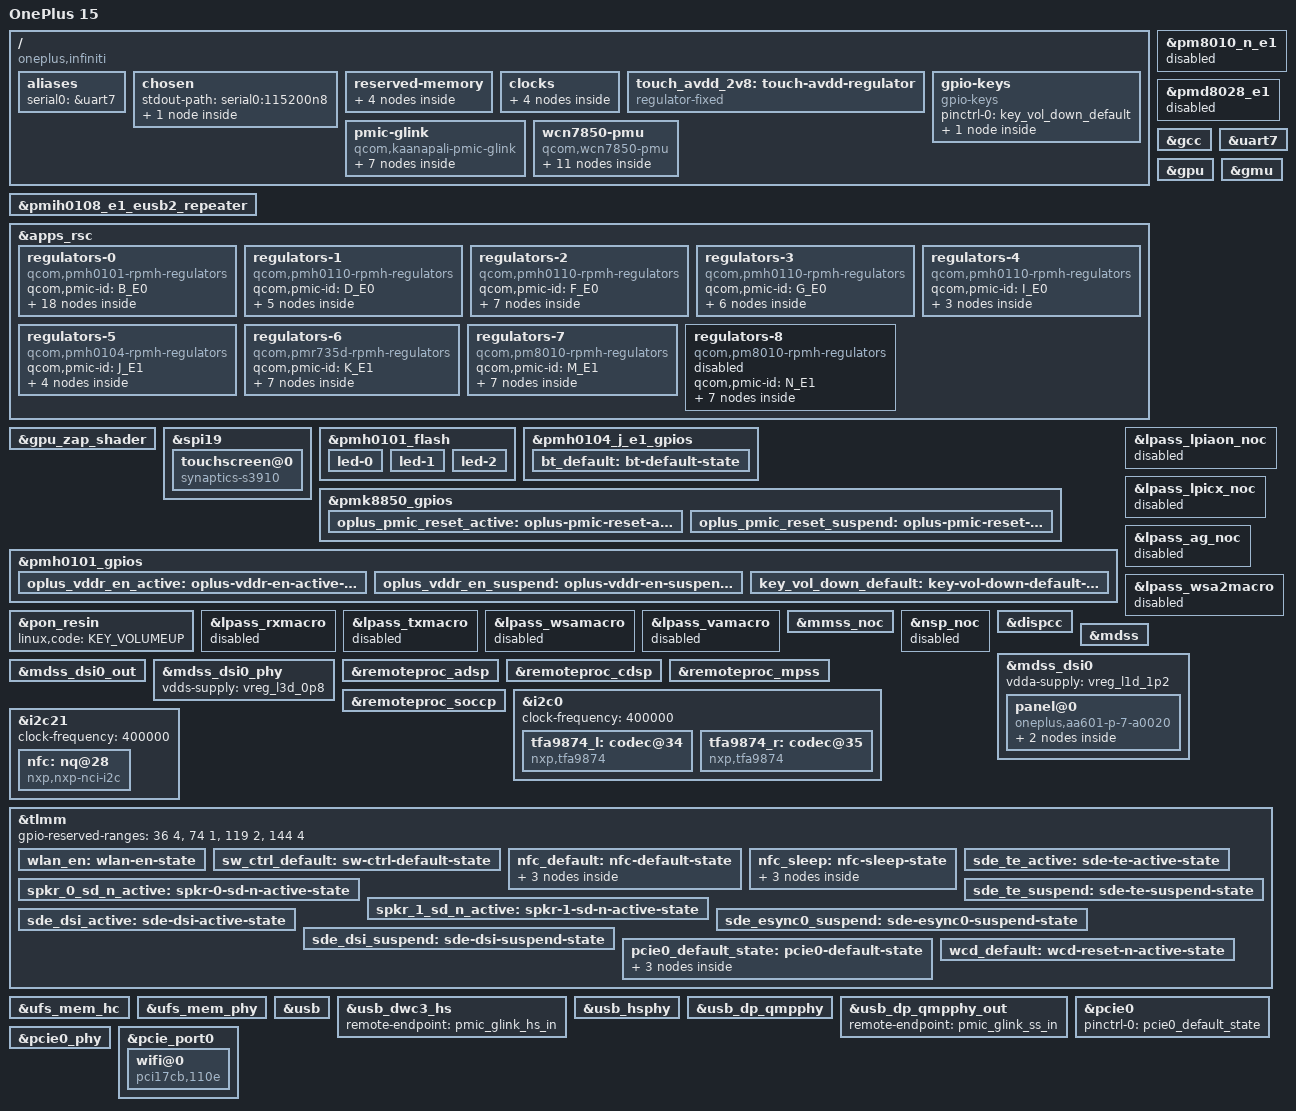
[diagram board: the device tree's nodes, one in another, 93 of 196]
// SPDX-License-Identifier: BSD-3-Clause
/dts-v1/;

#include <dt-bindings/arm/qcom,ids.h>
#include <dt-bindings/gpio/gpio.h>
#include <dt-bindings/input/linux-event-codes.h>
#include <dt-bindings/leds/common.h>
#include <dt-bindings/regulator/qcom,rpmh-regulator.h>
#include "kaanapali.dtsi"

#include "pm8010-kaanapali.dtsi"     /* SPMI1: SID-12/13   */
#include "pmd8028-kaanapali.dtsi"    /* SPMI1: SID-4       */
#include "pmh0101.dtsi"              /* SPMI0: SID-1       */
#include "pmh0104-kaanapali.dtsi"    /* SPMI1: SID-9       */
#include "pmh0110-kaanapali.dtsi"    /* SPMI0: SID-3/5/6/8 */
#include "pmih0108-kaanapali.dtsi"   /* SPMI1: SID-7       */
#include "pmk8850.dtsi"              /* SPMI0: SID-0       */
#include "pmr735d-kaanapali.dtsi"    /* SPMI1: SID-10      */

/delete-node/ &rmtfs_mem;

/ {
	model = "OnePlus 15";
	compatible = "oneplus,infiniti", "qcom,kaanapali";
	chassis-type = "handset";

	/* required for bootloader to select correct board */
	qcom,msm-id = <QCOM_ID_SM8850 0x20000>; /* SM8850 v2.0 */
	qcom,board-id = <0 0>;

	aliases {
		serial0 = &uart7;
	};

	chosen {
		#address-cells = <2>;
		#size-cells = <2>;
		ranges;

		stdout-path = "serial0:115200n8";

		framebuffer: framebuffer@b8000000 {
			compatible = "simple-framebuffer";
			reg = <0x0 0xfc800000 0x0 0x2b00000>;
			width = <1272>;
			height = <2772>;
			stride = <(1272 * 4)>;
			format = "a8r8g8b8";
		};
	};

	reserved-memory {

		bootloader_log_mem: botloader_mem@81ce4000 {
			reg = <0 0x81ce4000 0 0x10000>;
		};

		dump_device_info_mem: device_info_mem@a7f00000 {
			reg = <0 0xa7f00000 0 0x8000>;
			no-map;
		};

		/*
		 * The bootloader will only keep display hardware enabled
		 * if this memory region is named exactly 'splash_region'
		 */

		splash_memory: splash_region@fc800000 {
			reg = <0x0 0xfc800000 0x0 0x2b00000>;
			no-map;
		};

		/*
		 * The rmtfs memory region in downstream is 'dynamically allocated'
		 * but given the same address every time. Hard code it as this address is
		 * where the modem firmware expects it to be.
		 */
		rmtfs_mem: memory@d0d00000 {
			compatible = "qcom,rmtfs-mem";
			reg = <0x0 0xd0d00000 0x0 0x400000>;
			no-map;

			qcom,client-id = <1>;
			qcom,vmid = <QCOM_SCM_VMID_MSS_MSA>;
		};

	};

	/*
	 * Display bring-up: COLD-PROBE (mirrors the working Nubia Z80 Ultra kaanapali
	 * reference, same SoC). NO simple-framebuffer node and NO
	 * qcom,skip-mdss-reset: the UEFI continuous-splash handoff was the cause of
	 * the rainbow-bands / green-line freeze (simplefb clk_prepare_enable, or
	 * msm_mdss_enable() on the live UEFI-scanout MDP -> AXI/NoC stall). Cold-
	 * probe: msm_mdss_reset() idles the MDP first, the panel driver brings the
	 * display up later at the DRM modeset. Console is on serial0 (UART), not the
	 * framebuffer. The MDSS/dispcc/dsi0/dsi0_phy/mmss_noc nodes are enabled
	 * below; GPU/GMU/zap enabled for Adreno bring-up (stock PAS; SEA fixed
	 * in Mu-Silicium EFI memory map Reserv carveouts, not kernel tzmem).
	 */

	clocks {
		xo_board: xo-board {
			compatible = "fixed-clock";
			clock-frequency = <76800000>;
			#clock-cells = <0>;
		};

		sleep_clk: sleep-clk {
			compatible = "fixed-clock";
			clock-frequency = <32000>;
			#clock-cells = <0>;
		};

		bi_tcxo_div2: bi-tcxo-div2-clk {
			compatible = "fixed-factor-clock";
			#clock-cells = <0>;

			clocks = <&rpmhcc RPMH_CXO_CLK>;
			clock-mult = <1>;
			clock-div = <2>;
		};

		bi_tcxo_ao_div2: bi-tcxo-ao-div2-clk {
			compatible = "fixed-factor-clock";
			#clock-cells = <0>;

			clocks = <&rpmhcc RPMH_CXO_CLK_A>;
			clock-mult = <1>;
			clock-div = <2>;
		};
	};

	/*
	 * Touch AVDD is GPIO-switched on PMH0110_D GPIO9 (not L14B).
	 * Model as regulator-fixed for mainline avdd-supply consumers.
	 */
	touch_avdd_2v8: touch-avdd-regulator {
		compatible = "regulator-fixed";
		regulator-name = "touch_avdd_2v8";
		regulator-min-microvolt = <2800000>;
		regulator-max-microvolt = <2800000>;
		gpio = <&pmh0110_d_e0_gpios 9 GPIO_ACTIVE_HIGH>;
		enable-active-high;
	};

	gpio-keys {
		compatible = "gpio-keys";

		/*
		 * Infiniti (canoe-mtp / 24831): volume-down is wired to
		 * PMH0101 GPIO 6, not TLMM 101 (that is kaanapali-mtp/QRD).
		 * Volume-up stays on pmk8850 pon_resin.
		 */
		pinctrl-0 = <&key_vol_down_default>;
		pinctrl-names = "default";

		key-volume-down {
			label = "Volume Down";
			linux,code = <KEY_VOLUMEDOWN>;
			gpios = <&pmh0101_gpios 6 GPIO_ACTIVE_LOW>;
			debounce-interval = <32>;
			linux,can-disable;
			wakeup-source;
		};
	};

	pmic-glink {
		compatible = "qcom,kaanapali-pmic-glink";
		#address-cells = <1>;
		#size-cells = <0>;

		connector@0 {
			compatible = "usb-c-connector";
			reg = <0>;
			power-role = "dual";
			data-role = "dual";

			ports {
				#address-cells = <1>;
				#size-cells = <0>;

				port@0 {
					reg = <0>;

					pmic_glink_hs_in: endpoint {
						remote-endpoint = <&usb_dwc3_hs>;
					};
				};

				port@1 {
					reg = <1>;

					pmic_glink_ss_in: endpoint {
						remote-endpoint = <&usb_dp_qmpphy_out>;
					};
				};

				port@2 {
					reg = <2>;

					// pmic_glink_sbu: endpoint {
					// 	remote-endpoint = <&fsa4480_sbu_mux>;
					// };
				};

			};
		};
	};

};

&pmih0108_e1_eusb2_repeater {
	qcom,tune-usb2-preem = /bits/ 8 <0x4>;
	qcom,tune-usb2-slew = /bits/ 8 <0x2>;
	qcom,tune-usb2-disc-thres = /bits/ 8 <0x7>;
	qcom,tune-usb2-amplitude = /bits/ 8 <0xe>;
	qcom,squelch-detector-bp = <(-2000)>;
	vdd18-supply = <&vreg_l15b_1p8>;
	vdd3-supply = <&vreg_l5b_3p1>;

	status = "okay";
};

/*
 * SPMI1 PMICs not present on the Infiniti variant. The downstream canoe DT
 * (a multi-SKU superset) declares pmd8028 @ SID 0x4 and pm8010_n @ SID 0xd, but
 * on this device the SPMI arbiter NACKs both USIDs (status 0x3) and the RPMh
 * Command DB has no L*N_E1 entries, i.e. the silicon is absent. Disable the
 * nodes so the generic pmic-spmi driver does not try to probe them (avoids the
 * "transaction failed" WARN + -EIO probe failures). pm8010_m @ SID 0xc IS
 * present and stays enabled.
 */
&pm8010_n_e1 {
	status = "disabled";
};

&pmd8028_e1 {
	status = "disabled";
};

&apps_rsc {
	regulators-0 {
		compatible = "qcom,pmh0101-rpmh-regulators";
		qcom,pmic-id = "B_E0";

		vreg_bob1: bob1 {
			regulator-name = "vreg_bob1";
			regulator-min-microvolt = <3008000>;
			regulator-max-microvolt = <4000000>;
			regulator-initial-mode = <RPMH_REGULATOR_MODE_HPM>;
		};

		vreg_bob2: bob2 {
			regulator-name = "vreg_bob2";
			regulator-min-microvolt = <2704000>;
			regulator-max-microvolt = <3552000>;
			regulator-initial-mode = <RPMH_REGULATOR_MODE_HPM>;
		};

		vreg_l1b_1p8: ldo1 {
			regulator-name = "vreg_l1b_1p8";
			regulator-min-microvolt = <1800000>;
			regulator-max-microvolt = <1800000>;
			regulator-initial-mode = <RPMH_REGULATOR_MODE_AUTO>;
			regulator-allow-set-load;
			regulator-allowed-modes = <RPMH_REGULATOR_MODE_LPM
						   RPMH_REGULATOR_MODE_AUTO>;
		};

		vreg_l2b_3p0: ldo2 {
			regulator-name = "vreg_l2b_3p0";
			regulator-min-microvolt = <3008000>;
			regulator-max-microvolt = <3048000>;
			regulator-initial-mode = <RPMH_REGULATOR_MODE_AUTO>;
			regulator-allow-set-load;
			regulator-allowed-modes = <RPMH_REGULATOR_MODE_LPM
						   RPMH_REGULATOR_MODE_AUTO>;
		};

		vreg_l4b_1p8: ldo4 {
			regulator-name = "vreg_l4b_1p8";
			regulator-min-microvolt = <1800000>;
			regulator-max-microvolt = <1800000>;
			regulator-initial-mode = <RPMH_REGULATOR_MODE_AUTO>;
			regulator-allow-set-load;
			regulator-allowed-modes = <RPMH_REGULATOR_MODE_LPM
						   RPMH_REGULATOR_MODE_AUTO>;
		};

		vreg_l5b_3p1: ldo5 {
			regulator-name = "vreg_l5b_3p1";
			regulator-min-microvolt = <3100000>;
			regulator-max-microvolt = <3148000>;
			regulator-initial-mode = <RPMH_REGULATOR_MODE_AUTO>;
			regulator-allow-set-load;
			regulator-allowed-modes = <RPMH_REGULATOR_MODE_LPM
						   RPMH_REGULATOR_MODE_AUTO>;
		};

		vreg_l6b_1p8: ldo6 {
			regulator-name = "vreg_l6b_1p8";
			regulator-min-microvolt = <1800000>;
			regulator-max-microvolt = <3008000>;
			regulator-initial-mode = <RPMH_REGULATOR_MODE_AUTO>;
			regulator-allow-set-load;
			regulator-allowed-modes = <RPMH_REGULATOR_MODE_LPM
						   RPMH_REGULATOR_MODE_AUTO>;
		};

		vreg_l7b_1p8: ldo7 {
			regulator-name = "vreg_l7b_1p8";
			regulator-min-microvolt = <1800000>;
			regulator-max-microvolt = <3008000>;
			regulator-initial-mode = <RPMH_REGULATOR_MODE_AUTO>;
			regulator-allow-set-load;
			regulator-allowed-modes = <RPMH_REGULATOR_MODE_LPM
						   RPMH_REGULATOR_MODE_AUTO>;
		};

		vreg_l8b_1p8: ldo8 {
			regulator-name = "vreg_l8b_1p8";
			regulator-min-microvolt = <1800000>;
			regulator-max-microvolt = <3008000>;
			regulator-initial-mode = <RPMH_REGULATOR_MODE_AUTO>;
			regulator-allow-set-load;
			regulator-allowed-modes = <RPMH_REGULATOR_MODE_LPM
						   RPMH_REGULATOR_MODE_AUTO>;
		};

		vreg_l9b_2p9: ldo9 {
			regulator-name = "vreg_l9b_2p9";
			regulator-min-microvolt = <2960000>;
			regulator-max-microvolt = <3008000>;
			regulator-initial-mode = <RPMH_REGULATOR_MODE_HPM>;
			regulator-allow-set-load;
			regulator-allowed-modes = <RPMH_REGULATOR_MODE_LPM
						   RPMH_REGULATOR_MODE_HPM>;
		};

		vreg_l10b_1p8: ldo10 {
			regulator-name = "vreg_l10b_1p8";
			regulator-min-microvolt = <1800000>;
			regulator-max-microvolt = <1800000>;
			regulator-initial-mode = <RPMH_REGULATOR_MODE_AUTO>;
			regulator-allow-set-load;
			regulator-allowed-modes = <RPMH_REGULATOR_MODE_LPM
						   RPMH_REGULATOR_MODE_AUTO>;
		};

		pmh0101_l11: vreg_l11b_1p0: ldo11 {
			regulator-name = "vreg_l11b_1p0";
			regulator-min-microvolt = <1200000>;
			regulator-max-microvolt = <1200000>;
			regulator-initial-mode = <RPMH_REGULATOR_MODE_AUTO>;
			regulator-allow-set-load;
			regulator-allowed-modes = <RPMH_REGULATOR_MODE_LPM
						   RPMH_REGULATOR_MODE_AUTO>;
		};

		pmh0101_l12: vreg_l12b_1p8: ldo12 {
			regulator-name = "vreg_l12b_1p8";
			regulator-min-microvolt = <1800000>;
			regulator-max-microvolt = <1800000>;
			regulator-initial-mode = <RPMH_REGULATOR_MODE_AUTO>;
			regulator-allow-set-load;
			regulator-allowed-modes = <RPMH_REGULATOR_MODE_LPM
						   RPMH_REGULATOR_MODE_AUTO>;
		};

		pmh0101_l13: vreg_l13b_3p0: ldo13 {
			regulator-name = "vreg_l13b_3p0";
			regulator-min-microvolt = <3000000>;
			regulator-max-microvolt = <3000000>;
			regulator-initial-mode = <RPMH_REGULATOR_MODE_AUTO>;
			regulator-allow-set-load;
			regulator-allowed-modes = <RPMH_REGULATOR_MODE_LPM
						   RPMH_REGULATOR_MODE_AUTO>;
		};

		vreg_l14b_3p2: ldo14 {
			regulator-name = "vreg_l14b_3p2";
			regulator-min-microvolt = <3200000>;
			regulator-max-microvolt = <3200000>;
			regulator-initial-mode = <RPMH_REGULATOR_MODE_AUTO>;
			regulator-allow-set-load;
			regulator-allowed-modes = <RPMH_REGULATOR_MODE_LPM
						   RPMH_REGULATOR_MODE_AUTO>;
		};

		vreg_l15b_1p8: ldo15 {
			regulator-name = "vreg_l15b_1p8";
			regulator-min-microvolt = <1800000>;
			regulator-max-microvolt = <1800000>;
			regulator-initial-mode = <RPMH_REGULATOR_MODE_AUTO>;
			regulator-allow-set-load;
			regulator-allowed-modes = <RPMH_REGULATOR_MODE_LPM
						   RPMH_REGULATOR_MODE_AUTO>;
		};

		vreg_l17b_2p5: ldo17 {
			regulator-name = "vreg_l17b_2p5";
			regulator-min-microvolt = <2504000>;
			regulator-max-microvolt = <2504000>;
			regulator-initial-mode = <RPMH_REGULATOR_MODE_HPM>;
			regulator-allow-set-load;
			regulator-allowed-modes = <RPMH_REGULATOR_MODE_LPM
						   RPMH_REGULATOR_MODE_HPM>;
		};

		vreg_l18b_1p2: ldo18 {
			regulator-name = "vreg_l18b_1p2";
			regulator-min-microvolt = <1200000>;
			regulator-max-microvolt = <1200000>;
			regulator-initial-mode = <RPMH_REGULATOR_MODE_AUTO>;
			regulator-allow-set-load;
			regulator-allowed-modes = <RPMH_REGULATOR_MODE_LPM
						   RPMH_REGULATOR_MODE_AUTO>;
		};
	};

	regulators-1 {
		compatible = "qcom,pmh0110-rpmh-regulators";
		qcom,pmic-id = "D_E0";

		vreg_s10d_1p0: smps10 {
			regulator-name = "vreg_s10d_1p0";
			regulator-min-microvolt = <1000000>;
			regulator-max-microvolt = <1100000>;
			regulator-initial-mode = <RPMH_REGULATOR_MODE_HPM>;
		};

		vreg_l1d_1p2: ldo1 {
			regulator-name = "vreg_l1d_1p2";
			regulator-min-microvolt = <1200000>;
			regulator-max-microvolt = <1256000>;
			regulator-initial-mode = <RPMH_REGULATOR_MODE_AUTO>;
			regulator-allow-set-load;
			regulator-allowed-modes = <RPMH_REGULATOR_MODE_LPM
						   RPMH_REGULATOR_MODE_AUTO>;
		};

		vreg_l2d_0p9: ldo2 {
			regulator-name = "vreg_l2d_0p9";
			regulator-min-microvolt = <912000>;
			regulator-max-microvolt = <958000>;
			regulator-initial-mode = <RPMH_REGULATOR_MODE_AUTO>;
			regulator-allow-set-load;
			regulator-allowed-modes = <RPMH_REGULATOR_MODE_LPM
						   RPMH_REGULATOR_MODE_AUTO>;
		};

		pmh0110_d_l3: vreg_l3d_0p8: ldo3 {
			regulator-name = "vreg_l3d_0p8";
			regulator-min-microvolt = <880000>;
			regulator-max-microvolt = <880000>;
			regulator-initial-mode = <RPMH_REGULATOR_MODE_AUTO>;
			regulator-allow-set-load;
			regulator-allowed-modes = <RPMH_REGULATOR_MODE_LPM
						   RPMH_REGULATOR_MODE_AUTO>;
		};

		vreg_l4d_1p2: ldo4 {
			regulator-name = "vreg_l4d_1p2";
			regulator-min-microvolt = <1200000>;
			regulator-max-microvolt = <1200000>;
			regulator-initial-mode = <RPMH_REGULATOR_MODE_AUTO>;
			regulator-allow-set-load;
			regulator-allowed-modes = <RPMH_REGULATOR_MODE_LPM
						   RPMH_REGULATOR_MODE_AUTO>;
		};
	};

	regulators-2 {
		compatible = "qcom,pmh0110-rpmh-regulators";
		qcom,pmic-id = "F_E0";

		vreg_s6f_0p5: smps6 {
			regulator-name = "vreg_s6f_0p5";
			regulator-min-microvolt = <300000>;
			regulator-max-microvolt = <570000>;
			regulator-initial-mode = <RPMH_REGULATOR_MODE_HPM>;
		};

		vreg_s7f_1p2: smps7 {
			regulator-name = "vreg_s7f_1p2";
			regulator-min-microvolt = <1224000>;
			regulator-max-microvolt = <1372000>;
			regulator-initial-mode = <RPMH_REGULATOR_MODE_HPM>;
		};

		vreg_s8f_1p8: smps8 {
			regulator-name = "vreg_s8f_1p8";
			regulator-min-microvolt = <1800000>;
			regulator-max-microvolt = <2000000>;
			regulator-initial-mode = <RPMH_REGULATOR_MODE_HPM>;
		};

		vreg_l1f_1p2: ldo1 {
			regulator-name = "vreg_l1f_1p2";
			regulator-min-microvolt = <1200000>;
			regulator-max-microvolt = <1200000>;
			regulator-initial-mode = <RPMH_REGULATOR_MODE_AUTO>;
			regulator-allow-set-load;
			regulator-allowed-modes = <RPMH_REGULATOR_MODE_LPM
						   RPMH_REGULATOR_MODE_AUTO>;
		};

		vreg_l2f_1p2: ldo2 {
			regulator-name = "vreg_l2f_1p2";
			regulator-min-microvolt = <1200000>;
			regulator-max-microvolt = <1200000>;
			regulator-initial-mode = <RPMH_REGULATOR_MODE_AUTO>;
			regulator-allow-set-load;
			regulator-allowed-modes = <RPMH_REGULATOR_MODE_LPM
						   RPMH_REGULATOR_MODE_AUTO>;
		};

		vreg_l3f_0p8: ldo3 {
			regulator-name = "vreg_l3f_0p8";
			regulator-min-microvolt = <880000>;
			regulator-max-microvolt = <936000>;
			regulator-initial-mode = <RPMH_REGULATOR_MODE_AUTO>;
			regulator-allow-set-load;
			regulator-allowed-modes = <RPMH_REGULATOR_MODE_LPM
						   RPMH_REGULATOR_MODE_AUTO>;
		};

		vreg_l4f_0p8: ldo4 {
			regulator-name = "vreg_l4f_0p8";
			regulator-min-microvolt = <880000>;
			regulator-max-microvolt = <912000>;
			regulator-initial-mode = <RPMH_REGULATOR_MODE_AUTO>;
			regulator-allow-set-load;
			regulator-allowed-modes = <RPMH_REGULATOR_MODE_LPM
						   RPMH_REGULATOR_MODE_AUTO>;
		};
	};

	regulators-3 {
		compatible = "qcom,pmh0110-rpmh-regulators";
		qcom,pmic-id = "G_E0";

		vreg_s7g_0p9: smps7 {
			regulator-name = "vreg_s7g_0p9";
			regulator-min-microvolt = <880000>;
			regulator-max-microvolt = <1100000>;
			regulator-initial-mode = <RPMH_REGULATOR_MODE_HPM>;
		};

		vreg_s9g_1p0: smps9 {
			regulator-name = "vreg_s9g_1p0";
			regulator-min-microvolt = <1000000>;
			regulator-max-microvolt = <1100000>;
			regulator-initial-mode = <RPMH_REGULATOR_MODE_HPM>;
		};

		vreg_l1g_1p2: ldo1 {
			regulator-name = "vreg_l1g_1p2";
			regulator-min-microvolt = <1200000>;
			regulator-max-microvolt = <1200000>;
			regulator-initial-mode = <RPMH_REGULATOR_MODE_AUTO>;
			regulator-allow-set-load;
			regulator-allowed-modes = <RPMH_REGULATOR_MODE_LPM
						   RPMH_REGULATOR_MODE_AUTO>;
		};

		vreg_l2g_1p8: ldo2 {
			regulator-name = "vreg_l2g_1p8";
			regulator-min-microvolt = <1800000>;
			regulator-max-microvolt = <1800000>;
			regulator-initial-mode = <RPMH_REGULATOR_MODE_AUTO>;
			regulator-allow-set-load;
			regulator-allowed-modes = <RPMH_REGULATOR_MODE_LPM
						   RPMH_REGULATOR_MODE_AUTO>;
		};

		vreg_l3g_1p2: ldo3 {
			regulator-name = "vreg_l3g_1p2";
			regulator-min-microvolt = <1200000>;
			regulator-max-microvolt = <1200000>;
			regulator-initial-mode = <RPMH_REGULATOR_MODE_AUTO>;
			regulator-allow-set-load;
			regulator-allowed-modes = <RPMH_REGULATOR_MODE_LPM
						   RPMH_REGULATOR_MODE_AUTO>;
		};

		vreg_l4g_0p9: ldo4 {
			regulator-name = "vreg_l4g_0p9";
			regulator-min-microvolt = <912000>;
			regulator-max-microvolt = <912000>;
			regulator-initial-mode = <RPMH_REGULATOR_MODE_AUTO>;
			regulator-allow-set-load;
			regulator-allowed-modes = <RPMH_REGULATOR_MODE_LPM
						   RPMH_REGULATOR_MODE_AUTO>;
		};
	};

	regulators-4 {
		compatible = "qcom,pmh0110-rpmh-regulators";
		qcom,pmic-id = "I_E0";

		vreg_s7i_0p9: smps7 {
			regulator-name = "vreg_s7i_0p9";
			regulator-min-microvolt = <900000>;
			regulator-max-microvolt = <972000>;
			regulator-initial-mode = <RPMH_REGULATOR_MODE_HPM>;
		};

		vreg_l2i_1p2: ldo2 {
			regulator-name = "vreg_l2i_1p2";
			regulator-min-microvolt = <1200000>;
			regulator-max-microvolt = <1200000>;
			regulator-initial-mode = <RPMH_REGULATOR_MODE_AUTO>;
			regulator-allow-set-load;
			regulator-allowed-modes = <RPMH_REGULATOR_MODE_LPM
						   RPMH_REGULATOR_MODE_AUTO>;
		};

		vreg_l3i_0p8: ldo3 {
			regulator-name = "vreg_l3i_0p8";
			regulator-min-microvolt = <880000>;
			regulator-max-microvolt = <920000>;
			regulator-initial-mode = <RPMH_REGULATOR_MODE_AUTO>;
			regulator-allow-set-load;
			regulator-allowed-modes = <RPMH_REGULATOR_MODE_LPM
						   RPMH_REGULATOR_MODE_AUTO>;
		};
	};

	regulators-5 {
		compatible = "qcom,pmh0104-rpmh-regulators";
		qcom,pmic-id = "J_E1";

		vreg_s1j_0p8: smps1 {
			regulator-name = "vreg_s1j_0p8";
			regulator-min-microvolt = <400000>;
			regulator-max-microvolt = <1000000>;
			regulator-initial-mode = <RPMH_REGULATOR_MODE_HPM>;
		};

		vreg_s2j_0p8: smps2 {
			regulator-name = "vreg_s2j_0p8";
			regulator-min-microvolt = <500000>;
			regulator-max-microvolt = <1100000>;
			regulator-initial-mode = <RPMH_REGULATOR_MODE_HPM>;
		};

		vreg_s3j_1p2: smps3 {
			regulator-name = "vreg_s3j_1p2";
			regulator-min-microvolt = <1200000>;
			regulator-max-microvolt = <1300000>;
			regulator-initial-mode = <RPMH_REGULATOR_MODE_HPM>;
		};

		vreg_s4j_0p7: smps4 {
			regulator-name = "vreg_s4j_0p7";
			regulator-min-microvolt = <300000>;
			regulator-max-microvolt = <1000000>;
			regulator-initial-mode = <RPMH_REGULATOR_MODE_HPM>;
		};
	};

	regulators-6 {
		compatible = "qcom,pmr735d-rpmh-regulators";
		qcom,pmic-id = "K_E1";

		vreg_l1k_0p8: ldo1 {
			regulator-name = "vreg_l1k_0p8";
			regulator-min-microvolt = <300000>;
			regulator-max-microvolt = <1100000>;
			regulator-initial-mode = <RPMH_REGULATOR_MODE_HPM>;
			regulator-allow-set-load;
			regulator-allowed-modes = <RPMH_REGULATOR_MODE_LPM
						   RPMH_REGULATOR_MODE_HPM>;
		};

		vreg_l2k_0p7: ldo2 {
			regulator-name = "vreg_l2k_0p7";
			regulator-min-microvolt = <700000>;
			regulator-max-microvolt = <1000000>;
			regulator-initial-mode = <RPMH_REGULATOR_MODE_HPM>;
			regulator-allow-set-load;
			regulator-allowed-modes = <RPMH_REGULATOR_MODE_LPM
						   RPMH_REGULATOR_MODE_HPM>;
		};

		vreg_l3k_1p2: ldo3 {
			regulator-name = "vreg_l3k_1p2";
			regulator-min-microvolt = <1200000>;
			regulator-max-microvolt = <1200000>;
			regulator-initial-mode = <RPMH_REGULATOR_MODE_HPM>;
			regulator-allow-set-load;
			regulator-allowed-modes = <RPMH_REGULATOR_MODE_LPM
						   RPMH_REGULATOR_MODE_HPM>;
		};

		vreg_l4k_1p0: ldo4 {
			regulator-name = "vreg_l4k_1p0";
			regulator-min-microvolt = <1000000>;
			regulator-max-microvolt = <1200000>;
			regulator-initial-mode = <RPMH_REGULATOR_MODE_HPM>;
			regulator-allow-set-load;
			regulator-allowed-modes = <RPMH_REGULATOR_MODE_LPM
						   RPMH_REGULATOR_MODE_HPM>;
		};

		vreg_l5k_0p7: ldo5 {
			regulator-name = "vreg_l5k_0p7";
			regulator-min-microvolt = <700000>;
			regulator-max-microvolt = <1000000>;
			regulator-initial-mode = <RPMH_REGULATOR_MODE_HPM>;
			regulator-allow-set-load;
			regulator-allowed-modes = <RPMH_REGULATOR_MODE_LPM
						   RPMH_REGULATOR_MODE_HPM>;
		};

		vreg_l6k_1p7: ldo6 {
			regulator-name = "vreg_l6k_1p7";
			regulator-min-microvolt = <1700000>;
			regulator-max-microvolt = <2000000>;
			regulator-initial-mode = <RPMH_REGULATOR_MODE_HPM>;
			regulator-allow-set-load;
			regulator-allowed-modes = <RPMH_REGULATOR_MODE_LPM
						   RPMH_REGULATOR_MODE_HPM>;
		};

		vreg_l7k_0p7: ldo7 {
			regulator-name = "vreg_l7k_0p7";
			regulator-min-microvolt = <700000>;
			regulator-max-microvolt = <848000>;
			regulator-initial-mode = <RPMH_REGULATOR_MODE_HPM>;
			regulator-allow-set-load;
			regulator-allowed-modes = <RPMH_REGULATOR_MODE_LPM
						   RPMH_REGULATOR_MODE_HPM>;
		};
	};

	regulators-7 {
		compatible = "qcom,pm8010-rpmh-regulators";
		qcom,pmic-id = "M_E1";

		vreg_l1m_1p0: ldo1 {
			regulator-name = "vreg_l1m_1p0";
			regulator-min-microvolt = <1000000>;
			regulator-max-microvolt = <1200000>;
			regulator-initial-mode = <RPMH_REGULATOR_MODE_HPM>;
			regulator-allow-set-load;
			regulator-allowed-modes = <RPMH_REGULATOR_MODE_LPM
						   RPMH_REGULATOR_MODE_HPM>;
		};

		vreg_l2m_1p0: ldo2 {
			regulator-name = "vreg_l2m_1p0";
			regulator-min-microvolt = <1096000>;
			regulator-max-microvolt = <1104000>;
			regulator-initial-mode = <RPMH_REGULATOR_MODE_HPM>;
			regulator-allow-set-load;
			regulator-allowed-modes = <RPMH_REGULATOR_MODE_LPM
						   RPMH_REGULATOR_MODE_HPM>;
		};

		vreg_l3m_2p8: ldo3 {
			regulator-name = "vreg_l3m_2p8";
			regulator-min-microvolt = <2800000>;
			regulator-max-microvolt = <2900000>;
			regulator-initial-mode = <RPMH_REGULATOR_MODE_HPM>;
		};

		vreg_l4m_2p2: ldo4 {
			regulator-name = "vreg_l4m_2p2";
			regulator-min-microvolt = <2200000>;
			regulator-max-microvolt = <2800000>;
			regulator-initial-mode = <RPMH_REGULATOR_MODE_HPM>;
		};

		vreg_l5m_1p2: ldo5 {
			regulator-name = "vreg_l5m_1p2";
			regulator-min-microvolt = <1200000>;
			regulator-max-microvolt = <1800000>;
			regulator-initial-mode = <RPMH_REGULATOR_MODE_HPM>;
		};

		vreg_l6m_2p2: ldo6 {
			regulator-name = "vreg_l6m_2p2";
			regulator-min-microvolt = <2200000>;
			regulator-max-microvolt = <2200000>;
			regulator-initial-mode = <RPMH_REGULATOR_MODE_HPM>;
		};

		vreg_l7m_2p8: ldo7 {
			regulator-name = "vreg_l7m_2p8";
			regulator-min-microvolt = <2800000>;
			regulator-max-microvolt = <2800000>;
			regulator-initial-mode = <RPMH_REGULATOR_MODE_HPM>;
		};
	};

	regulators-8 {
		compatible = "qcom,pm8010-rpmh-regulators";
		qcom,pmic-id = "N_E1";

		/* pm8010_n (SID 0xd) absent on Infiniti: L*N_E1 not in the
		 * RPMh Command DB. Disable so qcom-rpmh-regulator does not look
		 * up L1N_E1 (and L2N..L7N) and fail with -ENODEV.
		 */
		status = "disabled";

		vreg_l1n_1p1: ldo1 {
			regulator-name = "vreg_l1n_1p1";
			regulator-min-microvolt = <1096000>;
			regulator-max-microvolt = <1200000>;
			regulator-initial-mode = <RPMH_REGULATOR_MODE_HPM>;
			regulator-allow-set-load;
			regulator-allowed-modes = <RPMH_REGULATOR_MODE_LPM
						   RPMH_REGULATOR_MODE_HPM>;
		};

		vreg_l2n_1p2: ldo2 {
			regulator-name = "vreg_l2n_1p2";
			regulator-min-microvolt = <1200000>;
			regulator-max-microvolt = <1200000>;
			regulator-initial-mode = <RPMH_REGULATOR_MODE_HPM>;
			regulator-allow-set-load;
			regulator-allowed-modes = <RPMH_REGULATOR_MODE_LPM
						   RPMH_REGULATOR_MODE_HPM>;
		};

		vreg_l3n_1p8: ldo3 {
			regulator-name = "vreg_l3n_1p8";
			regulator-min-microvolt = <1800000>;
			regulator-max-microvolt = <1800000>;
			regulator-initial-mode = <RPMH_REGULATOR_MODE_HPM>;
		};

		vreg_l4n_1p8: ldo4 {
			regulator-name = "vreg_l4n_1p8";
			regulator-min-microvolt = <1800000>;
			regulator-max-microvolt = <1800000>;
			regulator-initial-mode = <RPMH_REGULATOR_MODE_HPM>;
		};

		vreg_l5n_2p8: ldo5 {
			regulator-name = "vreg_l5n_2p8";
			regulator-min-microvolt = <2800000>;
			regulator-max-microvolt = <2800000>;
			regulator-initial-mode = <RPMH_REGULATOR_MODE_HPM>;
		};

		vreg_l6n_2p8: ldo6 {
			regulator-name = "vreg_l6n_2p8";
			regulator-min-microvolt = <2800000>;
			regulator-max-microvolt = <2800000>;
			regulator-initial-mode = <RPMH_REGULATOR_MODE_HPM>;
		};

		vreg_l7n_3p3: ldo7 {
			regulator-name = "vreg_l7n_3p3";
			regulator-min-microvolt = <3304000>;
			regulator-max-microvolt = <3304000>;
			regulator-initial-mode = <RPMH_REGULATOR_MODE_HPM>;
		};
	};
};

&gcc {
	status = "okay";
};

&uart7 {
	status = "okay";
};

&gpu {
	/* GPU + GMU; zap via &gpu_zap_shader (stock qcom_mdt_load PAS). */
	status = "okay";
};

&gmu {
	/* Required alongside &gpu for the a8xx bring-up path. */
	status = "okay";
};

&gpu_zap_shader {
	/*
	 * Enable zap PAS (stock qcom_mdt_load + pas_auth_and_reset). The SEA
	 * on dma_alloc_coherent(__scm->dev) was fixed by Mu-Silicium EFI
	 * memory-map Reserv carveouts (not by use_tzmem). SECVID_TRUST_CNTL=0
	 * alone is ignored by TZ → hangcheck 00880005 without zap.
	 * gpu_microcode_mem is 8 KiB (same as canoe.dtsi); LOAD segment of
	 * Infiniti zap is ~1 KiB — no enlarge needed.
	 * Blob: qcom/kaanapali/OnePlus/Infiniti/gen80200_zap.mbn
	 * sha256 fc6e4d0d0cd7269b7a03c44d07dde677621c0a8d566c6b94fc20860f2e714b0b
	 */
	status = "okay";
	firmware-name = "qcom/kaanapali/OnePlus/Infiniti/gen80200_zap.mbn";
};

&spi19 {
	status = "okay";

	touchscreen@0 {
		compatible = "synaptics-s3910";
		reg = <0>;
		spi-max-frequency = <19000000>;

		interrupt-parent = <&tlmm>;
		/* S3910 holds INT low until the host reads the report: level-low,
		 * not edge-falling (edge misses events when INT stays low across
		 * back-to-back frames and on warm reboot).
		 */
		interrupts = <158 IRQ_TYPE_LEVEL_LOW>;

		reset-gpios = <&tlmm 159 GPIO_ACTIVE_LOW>;

		vdd-supply = <&vreg_l4b_1p8>;
		avdd-supply = <&touch_avdd_2v8>;

		/*
		 * S3910 reports coordinates in 0.1px sensor units, i.e. 10x
		 * the 1264x2780 active area, so the raw axis max is 12640x27800.
		 */
		touchscreen-size-x = <12640>;
		touchscreen-size-y = <27800>;

		synaptics,power-delay-ms = <200>;
		synaptics,reset-active-ms = <10>;
		synaptics,reset-delay-ms = <80>;

		status = "okay";
	};
};

&pmh0101_flash {
	status = "okay";

	led-0 {
		function = LED_FUNCTION_FLASH;
		function-enumerator = <0>;
		color = <LED_COLOR_ID_YELLOW>;
		led-sources = <1>, <4>;
		led-max-microamp = <500000>;
		flash-max-microamp = <2000000>;
		flash-max-timeout-us = <1280000>;
	};

	led-1 {
		function = LED_FUNCTION_FLASH;
		function-enumerator = <1>;
		color = <LED_COLOR_ID_WHITE>;
		led-sources = <2>, <3>;
		led-max-microamp = <500000>;
		flash-max-microamp = <2000000>;
		flash-max-timeout-us = <1280000>;
	};

	led-2 {
		function = LED_FUNCTION_FLASH;
		function-enumerator = <2>;
		color = <LED_COLOR_ID_AMBER>;
		led-sources = <1>, <2>, <3>, <4>;
		led-max-microamp = <500000>;
		flash-max-microamp = <2000000>;
		flash-max-timeout-us = <1280000>;
	};
};

&pmh0104_j_e1_gpios {
	bt_default: bt-default-state {
		pins = "gpio5";
		function = "normal";
		input-disable;
		output-enable;
		bias-disable;
		power-source = <1>;
	};
};


&pmk8850_gpios {
	/*
	 * OLED_PMIC_RST (panel enable-gpio 1). The PMIC GPIO power-source MUST be
	 * set to 1.8V (VIN0) or the panel power-IC reset rail sits at the wrong
	 * voltage, the panel never initializes -> DCS init wedges -> DPU command-DMA
	 * NoC/AXI stall at the first modeset. Mirrors the downstream canoe overlay.
	 */
	oplus_pmic_reset_active: oplus-pmic-reset-active-state {
		pins = "gpio1";
		power-source = <0>; /* 1.8V */
	};

	oplus_pmic_reset_suspend: oplus-pmic-reset-suspend-state {
		pins = "gpio1";
		power-source = <0>; /* 1.8V */
	};
};

&pmh0101_gpios {
	/* VDDR_SM_1P5_EN (panel enable-gpio 2) — power-source 1.8V. */
	oplus_vddr_en_active: oplus-vddr-en-active-state {
		pins = "gpio4";
		power-source = <0>; /* 1.8V */
	};

	oplus_vddr_en_suspend: oplus-vddr-en-suspend-state {
		pins = "gpio4";
		power-source = <0>; /* 1.8V */
	};

	/* Volume-down (canoe-mtp): PMH0101 gpio6, active-low, 1.8V pull-up. */
	key_vol_down_default: key-vol-down-default-state {
		pins = "gpio6";
		function = "normal";
		input-enable;
		bias-pull-up;
		power-source = <1>; /* 1.8V */
	};
};

&pon_resin {
	linux,code = <KEY_VOLUMEUP>;

	status = "okay";
};

/*
 * Bring-up: LPASS NoC QoS MMIO sits in the unpowered LCX/LMX island until
 * remoteproc_adsp loads; probing it now causes a sync external abort in
 * qcom_icc_rpmh_configure_qos(). Disable the LPASS NoC providers and ADSP
 * until audio bring-up.
 */
&lpass_lpiaon_noc {
	status = "disabled";
};

&lpass_lpicx_noc {
	status = "disabled";
};

&lpass_ag_noc {
	status = "disabled";
};

&lpass_wsa2macro {
	status = "disabled";
};

&lpass_rxmacro {
	status = "disabled";
};

&lpass_txmacro {
	status = "disabled";
};

&lpass_wsamacro {
	status = "disabled";
};

&lpass_vamacro {
	status = "disabled";
};

/*
 * Bring-up: MMSS/NSP NoC QoS MMIO sits in unpowered islands at cold UEFI
 * boot (same class of fault as LPASS NoC). qcom_icc_rpmh_configure_qos()
 * touches regmap before MMSS/NSP power sequencing is up -> sync external
 * abort. Not on the UFS/root path; aggre_noc/config_noc/system_noc/gem_noc
 * stay enabled.
 *
 * Display bring-up: mmss_noc is the MDP0->EBI1 interconnect provider for &mdss;
 * re-enable it. QoS MMIO stays skipped via cmdline icc-rpmh.qos_disable=1, so
 * only the provider is registered without touching the unpowered QoS island.
 * nsp_noc / cdsp stay disabled (compute, not display).
 */
&mmss_noc {
	status = "okay";
};

&nsp_noc {
	status = "disabled";
};

/*
 * Cold-probe MDSS display pipeline. Each node has its own status for
 * bisection. qcom,skip-mdss-reset is intentionally unset so msm_mdss_reset()
 * idles the MDP first.
 */
&dispcc {
	status = "okay";
};

&mdss {
	status = "okay";
};

&mdss_dsi0 {
	#address-cells = <1>;
	#size-cells = <0>;
	vdda-supply = <&vreg_l1d_1p2>;
	status = "okay";

	panel@0 {
		compatible = "oneplus,aa601-p-7-a0020";
		reg = <0>;

		pinctrl-0 = <&sde_dsi_active &sde_te_active &sde_esync0_suspend
			     &oplus_pmic_reset_active &oplus_vddr_en_active>;
		pinctrl-1 = <&sde_dsi_suspend &sde_te_suspend &sde_esync0_suspend
			     &oplus_pmic_reset_suspend &oplus_vddr_en_suspend>;
		pinctrl-names = "default", "sleep";

		reset-gpios = <&tlmm 171 GPIO_ACTIVE_LOW>;

		/*
		 * AA601 power-on: vddio -> vdd -> gpio1(PMK8850/1) ->
		 * gpio2(PMH0101/4) -> vci. The two PMIC enable-gpios are wired through
		 * the oplus_pmic_reset_* / oplus_vddr_en_* pinctrl states (power-source
		 * 1.8V) below; without that power-source the OLED_PMIC_RST /
		 * VDDR_SM_1P5_EN rails sit at the wrong voltage, the panel power-IC never
		 * enables, and the first DPU command-DMA modeset stalls the NoC/AXI bus.
		 */
		enable-gpios = <&pmk8850_gpios 1 GPIO_ACTIVE_HIGH>,
			       <&pmh0101_gpios 4 GPIO_ACTIVE_HIGH>;

		vci-supply = <&vreg_l13b_3p0>;
		vdd-supply = <&vreg_l11b_1p0>;
		vddio-supply = <&vreg_l12b_1p8>;

		port {
			panel0_in: endpoint {
				remote-endpoint = <&mdss_dsi0_out>;
			};
		};
	};
};

&mdss_dsi0_out {
	remote-endpoint = <&panel0_in>;
	data-lanes = <0 1 2 3>;
};

&mdss_dsi0_phy {
	vdds-supply = <&vreg_l3d_0p8>;
	status = "okay";
};

&remoteproc_adsp {
	firmware-name = "qcom/kaanapali/OnePlus/Infiniti/adsp.mbn",
			"qcom/kaanapali/OnePlus/Infiniti/adsp_dtb.mbn";

	status = "okay";
};

&remoteproc_cdsp {
	firmware-name = "qcom/kaanapali/OnePlus/Infiniti/cdsp.mbn",
			"qcom/kaanapali/OnePlus/Infiniti/cdsp_dtb.mbn";

	status = "okay";
};

&remoteproc_mpss {
	firmware-name = "qcom/kaanapali/OnePlus/Infiniti/modem.mbn",
			"qcom/kaanapali/OnePlus/Infiniti/modem_dtb.mbn";

	status = "okay";
};

&remoteproc_soccp {
	firmware-name = "qcom/kaanapali/OnePlus/Infiniti/soccp.mbn",
			"qcom/kaanapali/OnePlus/Infiniti/soccp_dtb.mbn";

	status = "okay";
};

&i2c0 {
	clock-frequency = <400000>;
	status = "okay";


	tfa9874_l: codec@34 { /* Top Speaker */
		compatible = "nxp,tfa9874";
		reg = <0x34>;
		reset-gpio = <&tlmm 2 GPIO_ACTIVE_HIGH>;
		sound-name-prefix = "Speaker Left";
		#sound-dai-cells = <1>;
		sound-channel = <0>;
	};

	tfa9874_r: codec@35 { /* Bottom Speaker */
		compatible = "nxp,tfa9874";
		reg = <0x35>;
		reset-gpio = <&tlmm 160 GPIO_ACTIVE_HIGH>;
		sound-name-prefix = "Speaker Right";
		#sound-dai-cells = <1>;
		sound-channel = <1>;
	};
};

&i2c21 {
	clock-frequency = <400000>;
	status = "okay";

	nfc: nq@28 {
		compatible = "nxp,nxp-nci-i2c";
		reg = <0x28>;
		enable-gpios = <&tlmm 34 GPIO_ACTIVE_HIGH>;
		interrupt-parent = <&tlmm>;
		interrupts = <75 0>;
		interrupt-names = "nfc_irq";
		pinctrl-names = "default", "sleep";
		pinctrl-0 = <&nfc_default>;
		pinctrl-1 = <&nfc_sleep>;
	};
};

&tlmm {
	gpio-reserved-ranges = <36 4>,  /* NFC eSE SPI */
			       <74 1>,  /* eSE */
			       <119 2>, /* SoCCP */
			       <144 4>; /* CXM UART */
	wlan_en: wlan-en-state {
		pins = "gpio16";
		function = "gpio";
		drive-strength = <8>;
		bias-pull-down;
	};

	sw_ctrl_default: sw-ctrl-default-state {
		pins = "gpio18";
		function = "gpio";
		bias-pull-down;
	};

	nfc_default: nfc-default-state {
		nfc_int_active: nfc_int_active-state {
			pins = "gpio75";
			function = "gpio";
			drive-strength = <2>;
			bias-pull-up;
		};

		nfc_enable_active: nfc_enable_active-state {
			pins = "gpio34";
			function = "gpio";
			drive-strength = <2>;
			bias-pull-up;
		};

		nfc_clk_req_active: nfc_clk_req_active-state {
			pins = "gpio35";
			function = "gpio";
			drive-strength = <2>;
			bias-pull-up;
		};
	};

	nfc_sleep: nfc-sleep-state {
		nfc_int_suspend: nfc_int_suspend-state {
			pins = "gpio75";
			function = "gpio";
			drive-strength = <2>;
			bias-pull-up;
		};

		nfc_enable_suspend: nfc_enable_suspend-state {
			pins = "gpio34";
			function = "gpio";
			drive-strength = <2>;
			bias-disable;
		};

		nfc_clk_req_suspend: nfc_clk_req_suspend-state {
			pins = "gpio35";
			function = "gpio";
			drive-strength = <2>;
			bias-disable;
		};
	};

	spkr_0_sd_n_active: spkr-0-sd-n-active-state {
		pins = "gpio76";
		function = "gpio";
		drive-strength = <16>;
		bias-disable;
	};

	spkr_1_sd_n_active: spkr-1-sd-n-active-state {
		pins = "gpio77";
		function = "gpio";
		drive-strength = <16>;
		bias-disable;
	};

	sde_te_active: sde-te-active-state {
		pins = "gpio86";
		function = "mdp_vsync";
		drive-strength = <2>;
		bias-pull-down;
	};

	sde_te_suspend: sde-te-suspend-state {
		pins = "gpio86";
		function = "mdp_vsync";
		drive-strength = <2>;
		bias-pull-down;
	};

	sde_esync0_suspend: sde-esync0-suspend-state {
		pins = "gpio88";
		function = "mdp_esync0_out";
		drive-strength = <2>;
		bias-pull-down;
	};

	sde_dsi_active: sde-dsi-active-state {
		pins = "gpio171";
		function = "gpio";
		drive-strength = <8>;
		bias-disable;
	};

	sde_dsi_suspend: sde-dsi-suspend-state {
		pins = "gpio171";
		function = "gpio";
		drive-strength = <2>;
		bias-pull-down;
	};

	pcie0_default_state: pcie0-default-state {
		perst-n-pins {
			pins = "gpio102";
			function = "gpio";
			drive-strength = <2>;
			bias-disable;
		};

		clkreq-n-pins {
			pins = "gpio103";
			function = "pcie0_clk_req_n";
			drive-strength = <2>;
			bias-pull-up;
		};

		wake-n-pins {
			pins = "gpio104";
			function = "gpio";
			drive-strength = <2>;
			bias-pull-up;
		};
	};

	wcd_default: wcd-reset-n-active-state {
		pins = "gpio161";
		function = "gpio";
		drive-strength = <16>;
		bias-disable;
	};
};

&ufs_mem_hc {
	reset-gpios = <&tlmm 217 GPIO_ACTIVE_LOW>;

	vcc-supply = <&vreg_l17b_2p5>;
	vcc-max-microamp = <1200000>;
	vccq-supply = <&vreg_l4d_1p2>;
	vccq-max-microamp = <1200000>;

	status = "okay";
};

&ufs_mem_phy {
	vdda-phy-supply = <&vreg_l4g_0p9>;
	vdda-pll-supply = <&vreg_l1d_1p2>;

	status = "okay";
};


&usb {
	usb-role-switch;
	maximum-speed = "super-speed";

	status = "okay";
};

&usb_dwc3_hs {
	remote-endpoint = <&pmic_glink_hs_in>;
};

&usb_hsphy {
	vdd-supply = <&vreg_l4f_0p8>;
	vdda12-supply = <&vreg_l1d_1p2>;

	phys = <&pmih0108_e1_eusb2_repeater>;

	status = "okay";
};

&usb_dp_qmpphy {
	vdda-phy-supply = <&vreg_l1d_1p2>;
	vdda-pll-supply = <&vreg_l4f_0p8>;

	status = "okay";
};

&usb_dp_qmpphy_out {
	remote-endpoint = <&pmic_glink_ss_in>;
};

/* WiFi: WCN786x (WCN7850 family) over PCIe0, ath12k. Mirrors kaanapali-mtp.dts. */
/ {
	wcn7850-pmu {
		compatible = "qcom,wcn7850-pmu";

		pinctrl-0 = <&bt_default>, <&sw_ctrl_default>, <&wlan_en>;
		pinctrl-names = "default";

		bt-enable-gpios = <&pmh0104_j_e1_gpios 5 GPIO_ACTIVE_HIGH>;
		wlan-enable-gpios = <&tlmm 16 GPIO_ACTIVE_HIGH>;

		vdd-supply = <&vreg_s2j_0p8>;
		vddio-supply = <&vreg_l2g_1p8>;
		vddio1p2-supply = <&vreg_l3g_1p2>;
		vddaon-supply = <&vreg_s7g_0p9>;
		vdddig-supply = <&vreg_s1j_0p8>;
		vddrfa1p2-supply = <&vreg_s7f_1p2>;
		vddrfa1p8-supply = <&vreg_s8f_1p8>;

		clocks = <&rpmhcc RPMH_RF_CLK1>;

		regulators {
			vreg_pmu_rfa_cmn: ldo0 {
				regulator-name = "vreg_pmu_rfa_cmn";
			};

			vreg_pmu_aon_0p59: ldo1 {
				regulator-name = "vreg_pmu_aon_0p59";
			};

			vreg_pmu_wlcx_0p8: ldo2 {
				regulator-name = "vreg_pmu_wlcx_0p8";
			};

			vreg_pmu_wlmx_0p85: ldo3 {
				regulator-name = "vreg_pmu_wlmx_0p85";
			};

			vreg_pmu_btcmx_0p85: ldo4 {
				regulator-name = "vreg_pmu_btcmx_0p85";
			};

			vreg_pmu_rfa_0p8: ldo5 {
				regulator-name = "vreg_pmu_rfa_0p8";
			};

			vreg_pmu_rfa_1p2: ldo6 {
				regulator-name = "vreg_pmu_rfa_1p2";
			};

			vreg_pmu_rfa_1p8: ldo7 {
				regulator-name = "vreg_pmu_rfa_1p8";
			};

			vreg_pmu_pcie_0p9: ldo8 {
				regulator-name = "vreg_pmu_pcie_0p9";
			};

			vreg_pmu_pcie_1p8: ldo9 {
				regulator-name = "vreg_pmu_pcie_1p8";
			};
		};
	};
};

&pcie0 {
	pinctrl-0 = <&pcie0_default_state>;
	pinctrl-names = "default";

	status = "okay";
};

&pcie0_phy {
	vdda-phy-supply = <&vreg_l3i_0p8>;
	vdda-pll-supply = <&vreg_l1d_1p2>;

	status = "okay";
};

&pcie_port0 {
	wake-gpios = <&tlmm 104 GPIO_ACTIVE_HIGH>;
	reset-gpios = <&tlmm 102 GPIO_ACTIVE_LOW>;

	wifi@0 {
		compatible = "pci17cb,110e";
		reg = <0x10000 0x0 0x0 0x0 0x0>;

		vddrfacmn-supply = <&vreg_pmu_rfa_cmn>;
		vddaon-supply = <&vreg_pmu_aon_0p59>;
		vddwlcx-supply = <&vreg_pmu_wlcx_0p8>;
		vddwlmx-supply = <&vreg_pmu_wlmx_0p85>;
		vddrfa0p8-supply = <&vreg_pmu_rfa_0p8>;
		vddrfa1p2-supply = <&vreg_pmu_rfa_1p2>;
		vddrfa1p8-supply = <&vreg_pmu_rfa_1p8>;
		vddpcie0p9-supply = <&vreg_pmu_pcie_0p9>;
		vddpcie1p8-supply = <&vreg_pmu_pcie_1p8>;
	};
};
